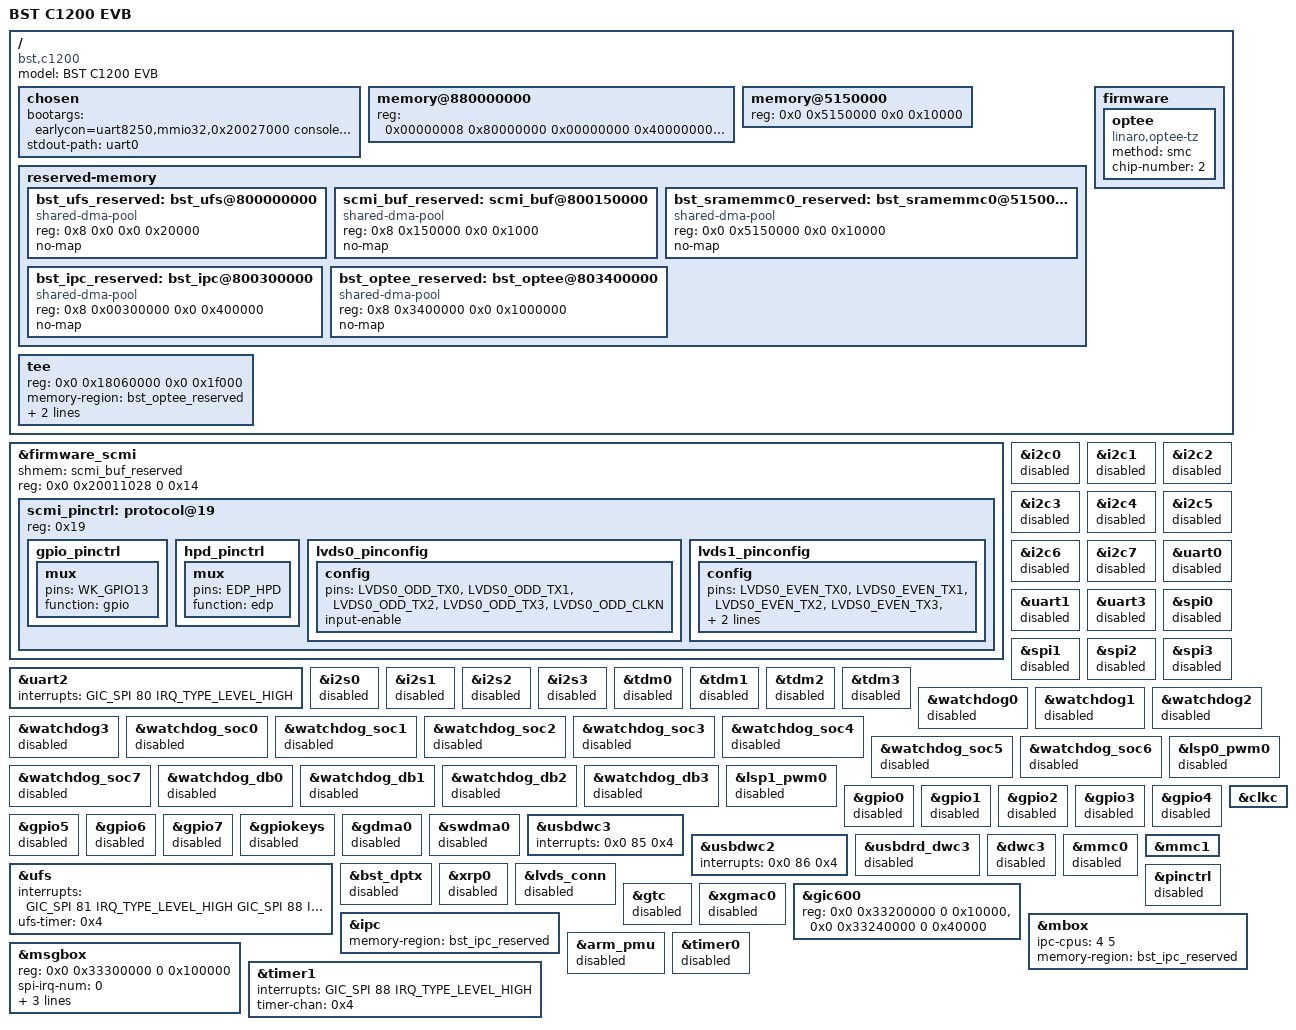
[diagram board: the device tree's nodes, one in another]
// SPDX-License-Identifier: GPL-2.0+
/dts-v1/;
#include "bstc1200.dtsi"
#include "bstc1200-db-cluster.dtsi"

/ {
	compatible = "bst,c1200";
	model = "BST C1200 EVB";

	chosen {
		bootargs = "earlycon=uart8250,mmio32,0x20027000 console=ttyS0,115200n8 rdinit=/sbin/init root=/dev/ram rw init=/linuxrc rodata=n";
		stdout-path = "uart0";
	};

// OS 1GB
	memory@880000000 {
		device_type = "memory";
		reg = <0x00000008 0x80000000 0x00000000 0x40000000
			   0x8 0x3400000 0x0 0x1000000
		>;
	};

//emmc
	memory@5150000 {
		device_type = "memory";
		reg = <0x0 0x5150000 0x0 0x10000>;
	};

	reserved-memory {
		#address-cells = <2>;
		#size-cells = <2>;
		ranges;

		bst_ufs_reserved: bst_ufs@800000000 {
			compatible = "shared-dma-pool";
			reg = <0x8 0x0 0x0 0x20000>;
			no-map;
		};

		scmi_buf_reserved: scmi_buf@800150000 {
			compatible = "shared-dma-pool";
			reg = <0x8 0x150000 0x0 0x1000>;
			no-map;
		};

		bst_sramemmc0_reserved: bst_sramemmc0@5150000{
			compatible = "shared-dma-pool";
			reg = <0x0 0x5150000 0x0 0x10000>;
			no-map;
		};

		bst_ipc_reserved: bst_ipc@800300000 {
			compatible = "shared-dma-pool";
			reg = <0x8 0x00300000 0x0 0x400000>;
 			no-map;
 		};



		bst_optee_reserved: bst_optee@803400000 {
			compatible = "shared-dma-pool";
			reg = <0x8 0x3400000 0x0 0x1000000>;
			no-map;
		};
	};

	firmware {
		optee {
			compatible = "linaro,optee-tz";
			method = "smc";
			chip-number = <2>;
		};
	};

	tee {
		#address-cells = <0x2>;
		#size-cells = <0x2>;
		reg = <0x0 0x18060000 0x0 0x1f000>;
		memory-region = <&bst_optee_reserved>;
		mbox-names = "bst-mbox";
		chip-number = <2>;
	};
};

&firmware_scmi {
	status = "okay";
	shmem = <&scmi_buf_reserved>;
	reg = <0x0 0x20011028 0 0x14>;
	
	
	 scmi_pinctrl: protocol@19 {
                        reg = <0x19>;
                        #pinctrl-cells = <0>;
			
			gpio_pinctrl:gpio_pinctrl {
        			mux {
            				pins = "WK_GPIO13";
            				function = "gpio";
        			};
    			};
			hpd_pinctrl:hpd_pinctrl {
				mux {
					pins = "EDP_HPD";
					function = "edp";
				};
			};
			lvds0_pinconfig:lvds0_pinconfig {
				config {
					pins = "LVDS0_ODD_TX0", "LVDS0_ODD_TX1", "LVDS0_ODD_TX2", "LVDS0_ODD_TX3", "LVDS0_ODD_CLKN";
					input-enable;
				};
			};
			lvds1_pinconfig:lvds1_pinconfig {
				config {
					pins = "LVDS0_EVEN_TX0", "LVDS0_EVEN_TX1", "LVDS0_EVEN_TX2", "LVDS0_EVEN_TX3", "LVDS0_EVEN_CLKN";
					input-enable;
				};
			};
        };
};


&i2c0 {
	status = "disable";
};
&i2c1 {
	status = "disable";
};
&i2c2 {
	status = "disable";
};
&i2c3 {
	status = "disable";
};
&i2c4 {
	status = "disable";
};
&i2c5 {
	status = "disable";
};
&i2c6 {
	status = "disable";
};
&i2c7 {
	status = "disable";
};

&uart0 {
	status = "disable";
};
&uart1 {
	status = "disable";
};
&uart2 {
	status = "okay";
	interrupts = <GIC_SPI 80 IRQ_TYPE_LEVEL_HIGH>;
};
&uart3 {
	status = "disable";
};

&spi0 {
	status = "disable";
};
&spi1 {
	status = "disable";
};
&spi2 {
	status = "disable";
};
&spi3 {
	status = "disable";
};

&i2s0 {
	status = "disable";
};
&i2s1 {
	status = "disable";
};
&i2s2 {
	status = "disable";
};
&i2s3 {
	status = "disable";
};

&tdm0 {
	status = "disable";
};
&tdm1 {
	status = "disable";
};
&tdm2 {
	status = "disable";
};
&tdm3 {
	status = "disable";
};

&watchdog0 {
	status = "disable";
};
&watchdog1 {
	status = "disable";
};
&watchdog2 {
	status = "disable";
};
&watchdog3 {
	status = "disable";
};
&watchdog_soc0 {
	status = "disable";
};
&watchdog_soc1 {
	status = "disable";
};
&watchdog_soc2 {
	status = "disable";
};
&watchdog_soc3 {
	status = "disable";
};

&watchdog_soc4 {
	status = "disable";
};
&watchdog_soc5 {
	status = "disable";
};
&watchdog_soc6 {
	status = "disable";
};
&watchdog_soc7 {
	status = "disable";
};
&watchdog_db0 {
	status = "disable";
};
&watchdog_db1 {
	status = "disable";
};
&watchdog_db2 {
	status = "disable";
};
&watchdog_db3 {
	status = "disable";
};

&lsp0_pwm0 {
	status = "disable";
};
&lsp1_pwm0 {
	status = "disable";
};

&gpio0 {
	status = "disable";
};
&gpio1 {
	status = "disable";
};
&gpio2 {
	status = "disable";
};
&gpio3 {
	status = "disable";
};
&gpio4 {
	status = "disable";
};
&gpio5 {
	status = "disable";
};
&gpio6 {
	status = "disable";
};
&gpio7 {
	status = "disable";
};
&gpiokeys {
	status = "disable";
};

&gdma0 {
	status = "disable";
};

&swdma0 {
	status = "disable";
};

&usbdwc3 {
	interrupts = <0x0 85 0x4>;
};
&usbdwc2 {
	interrupts = <0x0 86 0x4>;
};
&usbdrd_dwc3 {
	status = "disable";
};
&dwc3 {
	status = "disable";
};

&mmc0 {
	status = "disable";
};
&mmc1 {
	status = "okay";
};

&ufs {
	interrupts = <GIC_SPI 81 IRQ_TYPE_LEVEL_HIGH
				  GIC_SPI 88 IRQ_TYPE_LEVEL_HIGH>; 
	ufs-timer = <0x4>;
	status = "okay";
};

&bst_dptx {
	status = "disable";
};

&xrp0 {
	status = "disable";
};

&lvds_conn {
	status = "disable";
};

&pinctrl {
	status = "disable";
};

&clkc {
	status = "okay";
};

&gtc {
	status = "disable";
};

&xgmac0 {
	status = "disable";
};

&gic600 {
	status = "okay";
	reg = <0x0 0x33200000 0 0x10000>,	// GICD
			<0x0 0x33240000 0 0x40000>;	// GICR
};


&ipc {
	status = "okay";
	memory-region = <&bst_ipc_reserved>;
};

&mbox {
	status = "okay";
	ipc-cpus = <4 5>;
	memory-region = <&bst_ipc_reserved>;
};



&msgbox {
	status = "okay";
	reg =   <0x0 0x33300000 0 0x100000>; //db
	spi-irq-num = <0>;
	filter-num = <2>;
	interrupts =    <
	GIC_PPI 4 (GIC_CPU_MASK_SIMPLE(8) | IRQ_TYPE_LEVEL_LOW)
	GIC_PPI 15 (GIC_CPU_MASK_SIMPLE(8) | IRQ_TYPE_LEVEL_LOW)
	>;
	#mbox-cells = <0x1>;
};

&arm_pmu {
	status = "disable";
};

&timer0 {
       status = "disable";
};

&timer1 {
    interrupts = <GIC_SPI 88 IRQ_TYPE_LEVEL_HIGH>;
       timer-chan = <0x4>;
    status = "okay";
};
